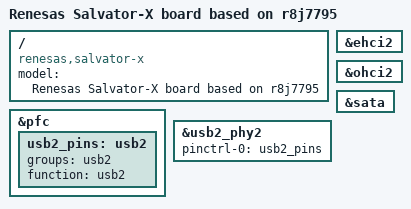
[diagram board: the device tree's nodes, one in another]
/*
 * Device Tree Source for the Salvator-X board
 *
 * Copyright (C) 2015 Renesas Electronics Corp.
 *
 * This file is licensed under the terms of the GNU General Public License
 * version 2.  This program is licensed "as is" without any warranty of any
 * kind, whether express or implied.
 */

/*
 * SSI-AK4613
 *
 * This command is required when Playback/Capture
 *
 *	amixer set "DVC Out" 100%
 *	amixer set "DVC In" 100%
 *
 * You can use Mute
 *
 *	amixer set "DVC Out Mute" on
 *	amixer set "DVC In Mute" on
 *
 * You can use Volume Ramp
 *
 *	amixer set "DVC Out Ramp Up Rate"   "0.125 dB/64 steps"
 *	amixer set "DVC Out Ramp Down Rate" "0.125 dB/512 steps"
 *	amixer set "DVC Out Ramp" on
 *	aplay xxx.wav &
 *	amixer set "DVC Out"  80%  // Volume Down
 *	amixer set "DVC Out" 100%  // Volume Up
 */

#define CPG_AUDIO_CLK_I		R8A7795_CLK_S0D4

/dts-v1/;
#include "r8j7795-4x1g.dtsi"
#include "salvator-x.dtsi"

/ {
	model = "Renesas Salvator-X board based on r8j7795";
	compatible = "renesas,salvator-x", "renesas,r8j7795", "renesas,r8a7795";
};

&ehci2 {
	status = "okay";
};

&ohci2 {
	status = "okay";
};

&pfc {
	usb2_pins: usb2 {
		groups = "usb2";
		function = "usb2";
	};
};

&sata {
	status = "okay";
};

&usb2_phy2 {
	pinctrl-0 = <&usb2_pins>;
	pinctrl-names = "default";

	status = "okay";
};
